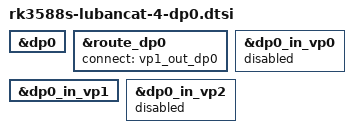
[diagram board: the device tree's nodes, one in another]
// SPDX-License-Identifier: (GPL-2.0+ OR MIT)
/*
 * Copyright (c) 2021 Rockchip Electronics Co., Ltd.
 * Copyright (c) 2023 EmbedFire <embedfire@embedfire.com>
 */

/dts-v1/;

/* dp0 display */
&dp0 {
	status = "okay";
};

&route_dp0 {
	status = "okay";
	connect = <&vp1_out_dp0>;
};

&dp0_in_vp0 {
	status = "disabled";
};

&dp0_in_vp1 {
	status = "okay";
};

&dp0_in_vp2 {
	status = "disabled";
};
